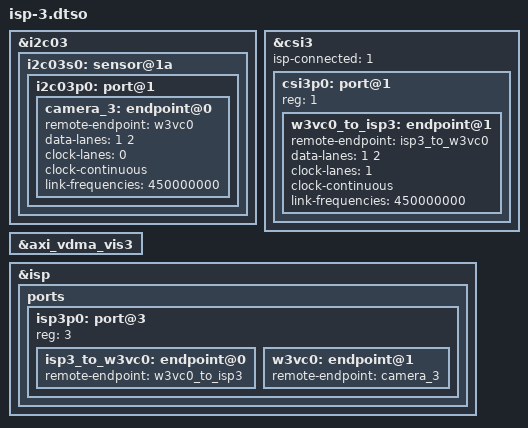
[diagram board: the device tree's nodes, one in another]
// SPDX-License-Identifier: (GPL-2.0+ OR MIT)
/*
 * Copyright (c) 2024 SiMa ai
 */

/dts-v1/;
/plugin/;

&i2c03 {
        i2c03s0: sensor@1a {
                i2c03p0: port@1 {
                        camera_3: endpoint@0 {
                                remote-endpoint = <&w3vc0>;
                                data-lanes = <1 2>;
                                clock-lanes = <0>;
                                clock-continuous;
                                link-frequencies = /bits/ 64 <450000000>;
                        };
                };
        };
};

&csi3 {
		status = "okay";
        isp-connected = <1>;
        csi3p0: port@1 {
                reg = <1>;
                w3vc0_to_isp3: endpoint@1 {
                        remote-endpoint = <&isp3_to_w3vc0>;
                        data-lanes = <1 2>;
                        clock-lanes = <1>;
                        clock-continuous;
                        link-frequencies = /bits/ 64 <450000000>;
                };
        };
};

&axi_vdma_vis3 {
        status = "okay";
};

&isp {
	status = "okay";
	ports {
		#address-cells = <1>;
		#size-cells = <0>;

        isp3p0: port@3 {
				reg = <3>;
                isp3_to_w3vc0: endpoint@0 {
                        remote-endpoint = <&w3vc0_to_isp3>;
                };
                w3vc0: endpoint@1 {
                        remote-endpoint = <&camera_3>;
                };
        };
	};
};
